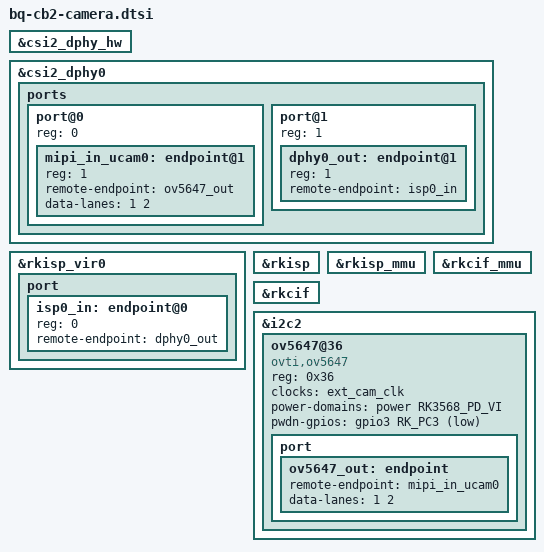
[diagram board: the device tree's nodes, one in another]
// SPDX-License-Identifier: (GPL-2.0+ OR MIT)
/*
 * Copyright (c) 2020 Rockchip Electronics Co., Ltd.
 *
 */
//#full
&csi2_dphy_hw {
	status = "okay";
};

&csi2_dphy0 {
	status = "okay";

	ports {
		#address-cells = <1>;
		#size-cells = <0>;

		port@0 {
			reg = <0>;
			#address-cells = <1>;
			#size-cells = <0>;

			mipi_in_ucam0: endpoint@1 {
				reg = <1>;
				remote-endpoint = <&ov5647_out>;
				data-lanes = <1 2>;
			};

		};

		port@1 {
			reg = <1>;
			#address-cells = <1>;
			#size-cells = <0>;

			dphy0_out: endpoint@1 {
				reg = <1>;
				remote-endpoint = <&isp0_in>;
			};
		};
	};
};

&rkisp_vir0 {
	status = "okay";

	port {
		#address-cells = <1>;
		#size-cells = <0>;

		isp0_in: endpoint@0 {
			reg = <0>;
			remote-endpoint = <&dphy0_out>;
		};
	};
};

&rkisp {
	status = "okay";
};

&rkisp_mmu {
	status = "okay";
};

&rkcif_mmu {
	status = "okay";
};

&rkcif {
	status = "okay";
};

&i2c2 {
	status = "okay";
	ov5647@36 {
		status = "okay";
		compatible = "ovti,ov5647";
		reg = <0x36>;
		clocks = <&ext_cam_clk>;
		clock-names = "ext_cam_ov5647_clk";
		power-domains = <&power RK3568_PD_VI>;
		pwdn-gpios = <&gpio3 RK_PC3 GPIO_ACTIVE_LOW>;
		port {
			ov5647_out: endpoint {
				remote-endpoint =<&mipi_in_ucam0>;//split:dphy1_in full: mipi_in_ucam0
                data-lanes = <1 2>;
            };
        };
	};
};
